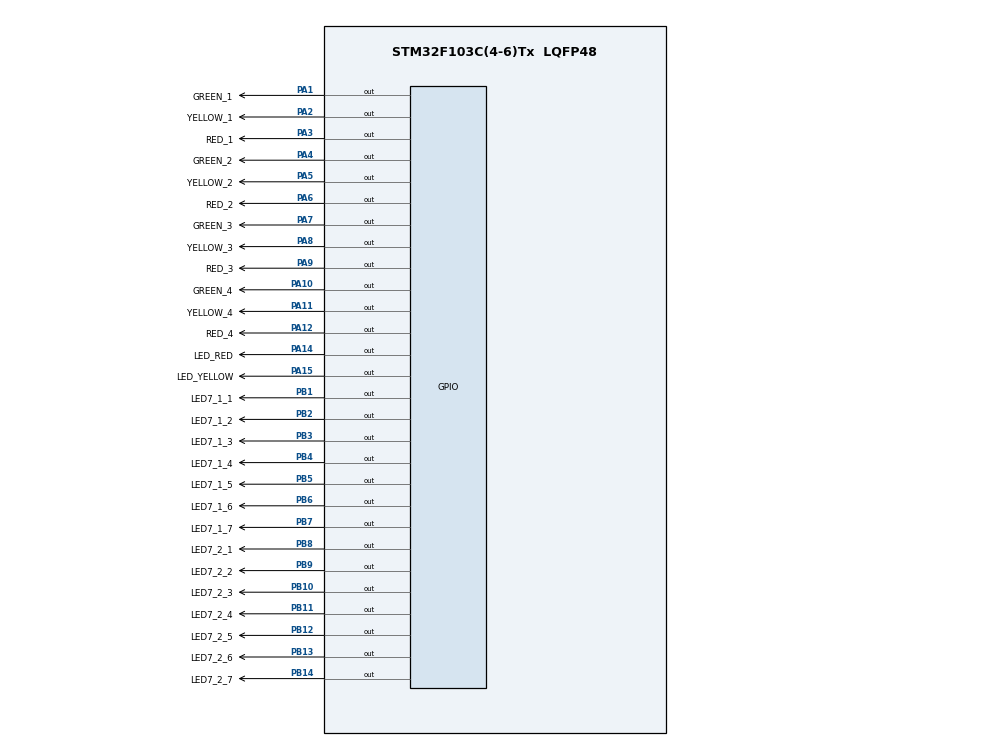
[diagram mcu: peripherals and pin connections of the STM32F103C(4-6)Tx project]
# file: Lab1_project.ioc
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Mcu.Family=STM32F1
Mcu.Name=STM32F103C(4-6)Tx
Mcu.Package=LQFP48
NVIC.PriorityGroup=NVIC_PRIORITYGROUP_4
PA1.GPIO_Label=GREEN_1
PA1.Signal=GPIO_Output
PA10.GPIO_Label=GREEN_4
PA10.Signal=GPIO_Output
PA11.GPIO_Label=YELLOW_4
PA11.Signal=GPIO_Output
PA12.GPIO_Label=RED_4
PA12.Signal=GPIO_Output
PA14.GPIO_Label=LED_RED
PA14.Signal=GPIO_Output
PA15.GPIO_Label=LED_YELLOW
PA15.Signal=GPIO_Output
PA2.GPIO_Label=YELLOW_1
PA2.Signal=GPIO_Output
PA3.GPIO_Label=RED_1
PA3.Signal=GPIO_Output
PA4.GPIO_Label=GREEN_2
PA4.Signal=GPIO_Output
PA5.GPIO_Label=YELLOW_2
PA5.Signal=GPIO_Output
PA6.GPIO_Label=RED_2
PA6.Signal=GPIO_Output
PA7.GPIO_Label=GREEN_3
PA7.Signal=GPIO_Output
PA8.GPIO_Label=YELLOW_3
PA8.Signal=GPIO_Output
PA9.GPIO_Label=RED_3
PA9.Signal=GPIO_Output
PB1.GPIO_Label=LED7_1_1
PB1.Signal=GPIO_Output
PB10.GPIO_Label=LED7_2_3
PB10.Signal=GPIO_Output
PB11.GPIO_Label=LED7_2_4
PB11.Signal=GPIO_Output
PB12.GPIO_Label=LED7_2_5
PB12.Signal=GPIO_Output
PB13.GPIO_Label=LED7_2_6
PB13.Signal=GPIO_Output
PB14.GPIO_Label=LED7_2_7
PB14.Signal=GPIO_Output
PB2.GPIO_Label=LED7_1_2
PB2.Signal=GPIO_Output
PB3.GPIO_Label=LED7_1_3
PB3.Signal=GPIO_Output
PB4.GPIO_Label=LED7_1_4
PB4.Signal=GPIO_Output
PB5.GPIO_Label=LED7_1_5
PB5.Signal=GPIO_Output
PB6.GPIO_Label=LED7_1_6
PB6.Signal=GPIO_Output
PB7.GPIO_Label=LED7_1_7
PB7.Signal=GPIO_Output
PB8.GPIO_Label=LED7_2_1
PB8.Signal=GPIO_Output
PB9.GPIO_Label=LED7_2_2
PB9.Signal=GPIO_Output
ProjectManager.HeapSize=0x200
ProjectManager.StackSize=0x400
ProjectManager.TargetToolchain=STM32CubeIDE
RCC.APB1Freq_Value=8000000
RCC.APB2Freq_Value=8000000
VP_SYS_VS_ND.Mode=No_Debug
board=custom

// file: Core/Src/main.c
/* USER CODE BEGIN Header */
/**
  ******************************************************************************
  * @file           : main.c
  * @brief          : Main program body
  ******************************************************************************
  * @attention
  *
  * <h2><center>&copy; Copyright (c) 2024 STMicroelectronics.
  * All rights reserved.</center></h2>
  *
  * This software component is licensed by ST under BSD 3-Clause license,
  * the "License"; You may not use this file except in compliance with the
  * License. You may obtain a copy of the License at:
  *                        opensource.org/licenses/BSD-3-Clause
  *
  ******************************************************************************
  */
/* USER CODE END Header */

#include "main.h"

/* USER CODE BEGIN Includes */

#include "ex1.h"
#include "ex2.h"
#include "ex3.h"
#include "ex4.h"
#include "ex5.h"
#include "ex7.h"
#include "ex8.h"
#include "ex9.h"
#include "ex10.h"
/* USER CODE END Includes */

void SystemClock_Config(void);
static void MX_GPIO_Init(void);

int main(void)
{

  /* MCU Configuration--------------------------------------------------------*/

  /* Reset of all peripherals, Initializes the Flash interface and the Systick. */
  HAL_Init();

  /* Configure the system clock */
  SystemClock_Config();

  /* Initialize all configured peripherals */
  MX_GPIO_Init();

  /* Infinite loop */
  /* USER CODE BEGIN WHILE */
  /* EX1*/
  HAL_GPIO_WritePin(GPIOA, LED_RED_Pin, RESET);
  HAL_GPIO_WritePin(GPIOA, LED_YELLOW_Pin, SET);

  /* 	EX2
   * traffic(GPIOA, RED_1_Pin, YELLOW_1_Pin, GREEN_1_Pin, GREEN); */

  /*	EX3
    traffic(GPIOA, RED_1_Pin, YELLOW_1_Pin, GREEN_1_Pin, GREEN);
    traffic(GPIOA, RED_3_Pin, YELLOW_3_Pin, GREEN_3_Pin, GREEN);
    traffic(GPIOA, RED_2_Pin, YELLOW_2_Pin, GREEN_2_Pin, RED);
    traffic(GPIOA, RED_4_Pin, YELLOW_4_Pin, GREEN_4_Pin, RED);
   */
  /*	EX4
   int num = 0;*/

  /* 	EX5
  traffic(GPIOA, RED_1_Pin, YELLOW_1_Pin, GREEN_1_Pin, GREEN);
  traffic(GPIOA, RED_3_Pin, YELLOW_3_Pin, GREEN_3_Pin, GREEN);
  traffic(GPIOA, RED_2_Pin, YELLOW_2_Pin, GREEN_2_Pin, RED);
  traffic(GPIOA, RED_4_Pin, YELLOW_4_Pin, GREEN_4_Pin, RED);
  */

  /* EX8 , EX9

  int num = 0;
  clearAllClock(GPIOA, GREEN_1_Pin, YELLOW_1_Pin, RED_1_Pin, GREEN_2_Pin, YELLOW_2_Pin, RED_2_Pin, GREEN_3_Pin, YELLOW_3_Pin, RED_3_Pin, GREEN_4_Pin, YELLOW_4_Pin, RED_4_Pin);
  */

  /*EX10
  clearAllClock(GPIOA, GREEN_1_Pin, YELLOW_1_Pin, RED_1_Pin, GREEN_2_Pin, YELLOW_2_Pin, RED_2_Pin, GREEN_3_Pin, YELLOW_3_Pin, RED_3_Pin, GREEN_4_Pin, YELLOW_4_Pin, RED_4_Pin);
   */
  while (1){

	  ex1_run();
	  /* ex2_run()*/
	  /* ex3_run();*/
	  /*
	  	  if(num>=10){
	  		  num = 0;
	  	  }
	  	  ex4_run(num);
	  	  num++;

	  	*/

	  /* ex5_run();*/

	  /*
	  led_on(GPIOA, GREEN_1_Pin);
	  led_on(GPIOA, GREEN_2_Pin);
	  HAL_Delay(500);
	  ex7_run();
	  HAL_Delay(500);
	  */

	 /*
	 if(num>=12){
		 num = 0;
	 }
	 clearAllClock(GPIOA, GREEN_1_Pin, YELLOW_1_Pin, RED_1_Pin, GREEN_2_Pin, YELLOW_2_Pin, RED_2_Pin, GREEN_3_Pin, YELLOW_3_Pin, RED_3_Pin, GREEN_4_Pin, YELLOW_4_Pin, RED_4_Pin);
	 HAL_Delay(200);
	 ex8_run(num);
	 num++;
	*/

	  /*
	  if(num>=12){
	  	num = 0;
	  	}
	  	setAllClock(GPIOA, GREEN_1_Pin, YELLOW_1_Pin, RED_1_Pin, GREEN_2_Pin, YELLOW_2_Pin, RED_2_Pin, GREEN_3_Pin, YELLOW_3_Pin, RED_3_Pin, GREEN_4_Pin, YELLOW_4_Pin, RED_4_Pin);

	  	HAL_Delay(200);
	  	ex9_run(num);
	  	num++;
	 */
	  /* ex10_run(); */
    /* USER CODE END WHILE */

    /* USER CODE BEGIN 3 */
	  	HAL_Delay(1000);

  }
  /* USER CODE END 3 */
}

void SystemClock_Config(void)
{
  RCC_OscInitTypeDef RCC_OscInitStruct = {0};
  RCC_ClkInitTypeDef RCC_ClkInitStruct = {0};

  /** Initializes the RCC Oscillators according to the specified parameters
  * in the RCC_OscInitTypeDef structure.
  */
  RCC_OscInitStruct.OscillatorType = RCC_OSCILLATORTYPE_HSI;
  RCC_OscInitStruct.HSIState = RCC_HSI_ON;
  RCC_OscInitStruct.HSICalibrationValue = RCC_HSICALIBRATION_DEFAULT;
  RCC_OscInitStruct.PLL.PLLState = RCC_PLL_NONE;
  if (HAL_RCC_OscConfig(&RCC_OscInitStruct) != HAL_OK)
  {
    Error_Handler();
  }
  /** Initializes the CPU, AHB and APB buses clocks
  */
  RCC_ClkInitStruct.ClockType = RCC_CLOCKTYPE_HCLK|RCC_CLOCKTYPE_SYSCLK
                              |RCC_CLOCKTYPE_PCLK1|RCC_CLOCKTYPE_PCLK2;
  RCC_ClkInitStruct.SYSCLKSource = RCC_SYSCLKSOURCE_HSI;
  RCC_ClkInitStruct.AHBCLKDivider = RCC_SYSCLK_DIV1;
  RCC_ClkInitStruct.APB1CLKDivider = RCC_HCLK_DIV1;
  RCC_ClkInitStruct.APB2CLKDivider = RCC_HCLK_DIV1;

  if (HAL_RCC_ClockConfig(&RCC_ClkInitStruct, FLASH_LATENCY_0) != HAL_OK)
  {
    Error_Handler();
  }
}

static void MX_GPIO_Init(void)
{
  GPIO_InitTypeDef GPIO_InitStruct = {0};

  /* GPIO Ports Clock Enable */
  __HAL_RCC_GPIOA_CLK_ENABLE();
  __HAL_RCC_GPIOB_CLK_ENABLE();

  /*Configure GPIO pin Output Level */
  HAL_GPIO_WritePin(GPIOA, GREEN_1_Pin|YELLOW_1_Pin|RED_1_Pin|GREEN_2_Pin
                          |YELLOW_2_Pin|RED_2_Pin|GREEN_3_Pin|YELLOW_3_Pin
                          |RED_3_Pin|GREEN_4_Pin|YELLOW_4_Pin|RED_4_Pin
                          |LED_RED_Pin|LED_YELLOW_Pin, GPIO_PIN_RESET);

  /*Configure GPIO pin Output Level */
  HAL_GPIO_WritePin(GPIOB, LED7_1_1_Pin|LED7_1_2_Pin|LED7_2_3_Pin|LED7_2_4_Pin
                          |LED7_2_5_Pin|LED7_2_6_Pin|LED7_2_7_Pin|LED7_1_3_Pin
                          |LED7_1_4_Pin|LED7_1_5_Pin|LED7_1_6_Pin|LED7_1_7_Pin
                          |LED7_2_1_Pin|LED7_2_2_Pin, GPIO_PIN_RESET);

  /*Configure GPIO pins : GREEN_1_Pin YELLOW_1_Pin RED_1_Pin GREEN_2_Pin
                           YELLOW_2_Pin RED_2_Pin GREEN_3_Pin YELLOW_3_Pin
                           RED_3_Pin GREEN_4_Pin YELLOW_4_Pin RED_4_Pin
                           LED_RED_Pin LED_YELLOW_Pin */
  GPIO_InitStruct.Pin = GREEN_1_Pin|YELLOW_1_Pin|RED_1_Pin|GREEN_2_Pin
                          |YELLOW_2_Pin|RED_2_Pin|GREEN_3_Pin|YELLOW_3_Pin
                          |RED_3_Pin|GREEN_4_Pin|YELLOW_4_Pin|RED_4_Pin
                          |LED_RED_Pin|LED_YELLOW_Pin;
  GPIO_InitStruct.Mode = GPIO_MODE_OUTPUT_PP;
  GPIO_InitStruct.Pull = GPIO_NOPULL;
  GPIO_InitStruct.Speed = GPIO_SPEED_FREQ_LOW;
  HAL_GPIO_Init(GPIOA, &GPIO_InitStruct);

  /*Configure GPIO pins : LED7_1_1_Pin LED7_1_2_Pin LED7_2_3_Pin LED7_2_4_Pin
                           LED7_2_5_Pin LED7_2_6_Pin LED7_2_7_Pin LED7_1_3_Pin
                           LED7_1_4_Pin LED7_1_5_Pin LED7_1_6_Pin LED7_1_7_Pin
                           LED7_2_1_Pin LED7_2_2_Pin */
  GPIO_InitStruct.Pin = LED7_1_1_Pin|LED7_1_2_Pin|LED7_2_3_Pin|LED7_2_4_Pin
                          |LED7_2_5_Pin|LED7_2_6_Pin|LED7_2_7_Pin|LED7_1_3_Pin
                          |LED7_1_4_Pin|LED7_1_5_Pin|LED7_1_6_Pin|LED7_1_7_Pin
                          |LED7_2_1_Pin|LED7_2_2_Pin;
  GPIO_InitStruct.Mode = GPIO_MODE_OUTPUT_PP;
  GPIO_InitStruct.Pull = GPIO_NOPULL;
  GPIO_InitStruct.Speed = GPIO_SPEED_FREQ_LOW;
  HAL_GPIO_Init(GPIOB, &GPIO_InitStruct);

}

void Error_Handler(void)
{
  __disable_irq();
  while (1)
  {
  }
}

/************************ (C) COPYRIGHT STMicroelectronics *****END OF FILE****/
